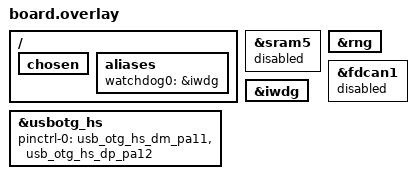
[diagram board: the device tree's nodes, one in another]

&sram5 {
    status = "disabled";
};

&rng {
    status = "okay";
};

&fdcan1 {
    status = "disabled";
};

/ {
    chosen {
        /delete-property/ zephyr,canbus;
    };
};

zephyr_udc0: &usbotg_hs {
    pinctrl-0 = <&usb_otg_hs_dm_pa11 &usb_otg_hs_dp_pa12>;
    pinctrl-names = "default";
    status = "okay";
};

// Enable the SoC watchdog and expose it through the `watchdog0` alias
// (Zephyr's watchdog sample selection) for the watchdog module. The IWDG
// doesn't start on boot (START_ACTIVE_BY_DEFAULT is off); it only arms when
// Python code sets a mode. It cannot be stopped once armed, like the native
// STM32 CircuitPython port.
&iwdg {
	status = "okay";
};

/ {
	aliases {
		watchdog0 = &iwdg;
	};
};

#include "../../../app.overlay"
